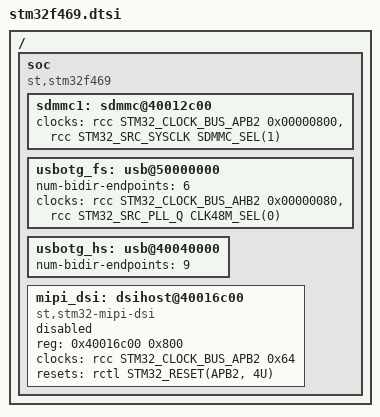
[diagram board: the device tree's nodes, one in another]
/*
 * Copyright (c) 2017 Linaro Limited
 *
 * SPDX-License-Identifier: Apache-2.0
 */

#include <st/f4/stm32f429.dtsi>
#include <zephyr/dt-bindings/mipi_dsi/mipi_dsi.h>

/ {
	soc {
		compatible = "st,stm32f469", "st,stm32f4", "simple-bus";

		sdmmc1: sdmmc@40012c00 {
			clocks = <&rcc STM32_CLOCK_BUS_APB2 0x00000800>,
				 <&rcc STM32_SRC_SYSCLK SDMMC_SEL(1)>;
		};

		usbotg_fs: usb@50000000 {
			num-bidir-endpoints = <6>;
			clocks = <&rcc STM32_CLOCK_BUS_AHB2 0x00000080>,
				 <&rcc STM32_SRC_PLL_Q CLK48M_SEL(0)>;
		};

		usbotg_hs: usb@40040000 {
			num-bidir-endpoints = <9>;
		};

		mipi_dsi: dsihost@40016c00 {
			compatible = "st,stm32-mipi-dsi";
			#address-cells = <1>;
			#size-cells = <0>;
			reg = <0x40016c00 0x800>;
			clock-names = "dsiclk";
			clocks = <&rcc STM32_CLOCK_BUS_APB2 0x64>;
			resets = <&rctl STM32_RESET(APB2, 4U)>;
			status = "disabled";
		};
	};
};
